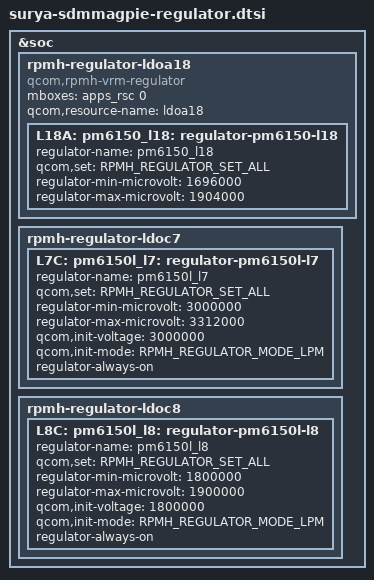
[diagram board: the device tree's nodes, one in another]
#include <dt-bindings/regulator/qcom,rpmh-regulator.h>

&soc {
	rpmh-regulator-ldoa18 {
		compatible = "qcom,rpmh-vrm-regulator";
		mboxes = <&apps_rsc 0>;
		qcom,resource-name = "ldoa18";
		L18A: pm6150_l18: regulator-pm6150-l18 {
			regulator-name = "pm6150_l18";
			qcom,set = <RPMH_REGULATOR_SET_ALL>;
			regulator-min-microvolt = <1696000>;
			regulator-max-microvolt = <1904000>;
		};
	};

	rpmh-regulator-ldoc7 {
		L7C: pm6150l_l7: regulator-pm6150l-l7 {
			regulator-name = "pm6150l_l7";
			qcom,set = <RPMH_REGULATOR_SET_ALL>;
			regulator-min-microvolt = <3000000>;
			regulator-max-microvolt = <3312000>;
			qcom,init-voltage = <3000000>;
			qcom,init-mode = <RPMH_REGULATOR_MODE_LPM>;
			regulator-always-on;
		};
	};

	rpmh-regulator-ldoc8 {
		L8C: pm6150l_l8: regulator-pm6150l-l8 {
			regulator-name = "pm6150l_l8";
			qcom,set = <RPMH_REGULATOR_SET_ALL>;
			regulator-min-microvolt = <1800000>;
			regulator-max-microvolt = <1900000>;
			qcom,init-voltage = <1800000>;
			qcom,init-mode = <RPMH_REGULATOR_MODE_LPM>;
			regulator-always-on;
		};
	};
};
